# RN821X_RN721X_SOC_B register map
File version: v1.0.6
CPU: CM0 r0p0, little endian, no MPU, no FPU, 3 interrupt priority bits
Registers are 32-bit, read-write, reset 0x0 unless marked. A register's access mark holds for its fields unless they carry their own. Offsets are from the block's base; [hi:lo] are bit positions; {n}, {i} and the like mark numbered series; 'fields as' and 'values as' point back to an identical list.

## KBI — key detection
Base 0x40028000
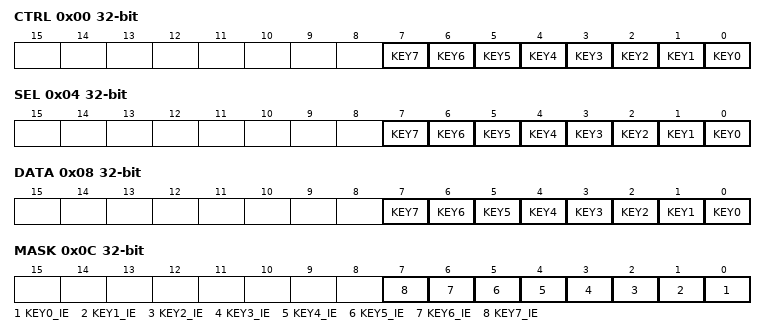
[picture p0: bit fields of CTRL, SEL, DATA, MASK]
0x00 CTRL — KBI control register
  [n] KEY{n} (n=0..7) — KBI KEY{n} enable/disable bit
    1=EN (KBI KEY{n} enable); 0=DIS (KBI KEY{n} disable)
0x04 SEL — KBI trigger mode select register
  [all] fields
    0=PE (KBI select posedge sampling); 1=NE (KBI select negedge sampling)
  [n] KEY{n} (n=0..7) — KBI KEY{n} posedge/negedge selection bit
0x08 DATA — KBI data register
  [all] fields
    1=PD (KEY pressed); 0=NUL (KEY not be pressed)
  [n] KEY{n} write-1-clears (n=0..7) — KBI KEY{n} data bit indicate key pressed or not
0x0C MASK — KBI interrupt mask register
  [n] KEY{n}_IE (n=0..7) — KBI KEY{n} interrupt enable/disable bit

## LCD — liquid crystal display
Base 0x40048000
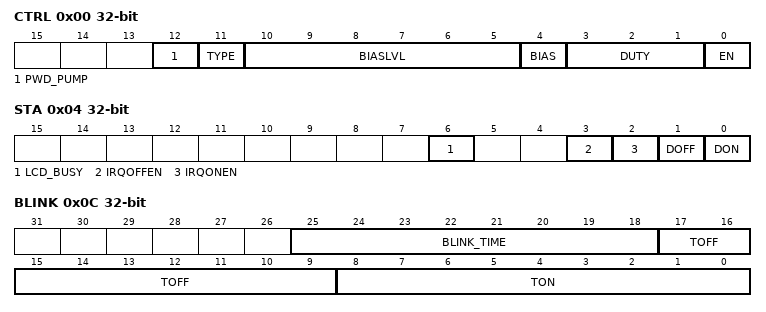
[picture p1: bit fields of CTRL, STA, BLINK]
0x00 CTRL — LCD control register
  [12] PWD_PUMP — LCD PUMP disable/enable bit
    0=EN (LCD PUMP enable); 1=DIS (LCD PUMP disable)
  [11] TYPE — LCD drive type selection bit
    0=A (select LCD drive type A as LCD drive type); 1=B (select LCD drive type B as LCD drive type)
  [10:5] BIASLVL — LCD voltage Bias configuration bits
  [4] BIAS — LCD voltage bias control bit
    0=1_3 (select LCD bias as 1/3 voltage bias); 1=1_4 (select LCD bias as 1/3 voltage bias)
  [3:1] DUTY — LCD duty cycle selection bits
    0=STA (static output (COM0)); 1=1_2 (duty cycle = 1/2 (COM0~1)); 2=1_3 (duty cycle = 1/3 (COM0~2)); 3=1_4 (duty cycle = 1/4 (COM0~3)); 4=1_6 (duty cycle = 1/6 (COM0~5)); 5=1_8 (duty cycle = 1/8 (COM0~7))
  [0] EN — LCD module enable/disable bit
0x04 STA — LCD status register
  [6] LCD_BUSY ro — LCD Busy Bit
  [3] IRQOFFEN — Display Off IRQ Enble Bit
  [2] IRQONEN — Display On IRQ Enble Bit
  [1] DOFF write-1-clears — Display Off Pending Bit
    0=NUL (LCD Display Off did not occured); 1=OCC (LCD Display Off occured)
  [0] DON write-1-clears — Display On Pending Bit
    0=NUL (LCD Display On did not occured); 1=OCC (LCD Display On occured)
0x08 CLKDIV — LCD clock divisor register
  [7:0] CLKDIV — LCD clock divisor configuration bits
0x0C BLINK — LCD blink control register
  [25:18] BLINK_TIME — blink duration configuration bits
  [17:9] TOFF — blink off duration configuration bits
  [8:0] TON — blink on duration configuration bits
0x10 PS — LCD PUMP set-up duration register
  [15:0] PS — PUMP Set-up duration configuration bits,duration equal to 30.5us * (4 + PS)
{0x20+i} BUF{i} 8-bit (i=0..35) — Data register of SEG({i}) COM[7:0]
  [7:0] BUF{i} — Data bits of SEG({i}) COM[7:0]
0x44 BUF36 8-bit — Data register of SEG(36) COM[7:1]
  [7:0] BUF36 — Data bits of SEG(36) COM[7:1]
0x45 BUF37 8-bit — Data register of SEG(37) COM[7:1]
  [7:0] BUF37 — Data bits of SEG(37) COM[7:1]

## NVM — no voltage module
Base 0x40040000
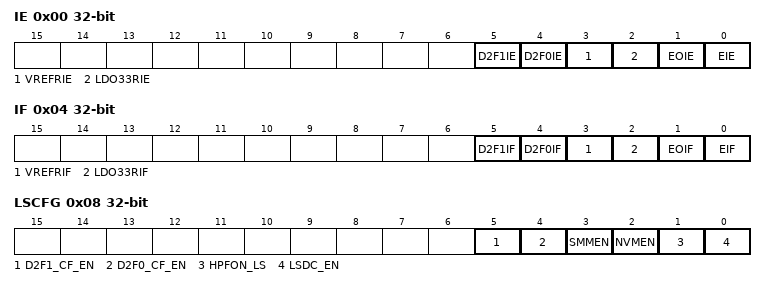
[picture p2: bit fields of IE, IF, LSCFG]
0x00 IE — interrupt enables
  [5] D2F1IE — d2f1 pulse interrupt enable
    0=DIS (do not generate interrupt when d2f1 pulse is output); 1=EN (generate interrupt when d2f1 pulse is output)
  [4] D2F0IE — d2f0 pulse interrupt enable
    0=DIS (do not generate interrupt when d2f0 pulse is output); 1=EN (generate interrupt when d2f0 pulse is output)
  [3] VREFRIE — VREF reset interrupt enable
    0=DIS (do not generate interrupt when VREF reset found); 1=EN (generate interrupt when VREF reset found)
  [2] LDO33RIE — LDO33 reset interrupt enable
    0=DIS (do not generate interrupt when reset found in LDO33 power domain); 1=EN (generate interrupt when reset found in LDO33 power domain)
  [1] EOIE — NV end and overflow interrupt enable
    0=DIS (do not generate interrupt when NV computation ends and NV value beyond threshold); 1=EN (generate interrupt when NV computation ends and NV value beyond threshold)
  [0] EIE — NV end interrupt enable
    0=DIS (do not generate interrupt when NV computation ends); 1=EN (generate interrupt when NV computation ends)
0x04 IF — interrupt flag
  [5] D2F1IF — d2f1 impulse interrupt flag
    0=NULL (no pending event of d2f1 impulse); 1=OCC (pending event of d2f1 impulse interrupt flag)
  [4] D2F0IF — d2f0 impulse interrupt flag
    0=NULL (no pending event of d2f0 impulse); 1=OCC (pending event of d2f0 impulse interrupt flag)
  [3] VREFRIF — VREF reset interrupt flag
    0=NULL (no pending event of VREF domain reset); 1=OCC (pending event of VREF domain reset found)
  [2] LDO33RIF — LDO33 reset interrupt flag
    0=NULL (no pending event of LDO33 power domain reset); 1=OCC (pending event of LDO33 power domain reset found)
  [1] EOIF — NV end and overflow interrupt flag
    0=NULL (no pending event of NV computation ends and NV value beyond threshold); 1=OCC (pending event of NV computation ends and NV value beyond threshold found)
  [0] EIF — NV end interrupt flag
    values as EOIF
0x08 LSCFG — NV config
  [5] D2F1_CF_EN — SMM enable
    0=DIS (D2F1 pulse not output to io); 1=EN (D2F1 pulse output to io)
  [4] D2F0_CF_EN — SMM enable
    0=DIS; 1=EN
  [3] SMMEN — SMM enable
    0=DIS (RMS updated every 20ms); 1=EN (RMS updated every 80ms)
  [2] NVMEN — module enable
    0=DIS (disabled); 1=EN (enabled)
  [1] HPFON_LS — high pass filter enable
    0=DIS (disabled); 1=EN (enabled)
  [0] LSDC_EN — automatic DC offset calibration enable
    0=DIS (disabled); 1=EN (enabled)
0x0C LSDCOS — NV measurement DC offset.
  [23:0] LSDCOS
0x10 LSTHO — NV measurement threshold
  [23:0] LSTHO
0x14 LSRMS ro — IA cyclic updated NV measurement RMS
  [23:0] LSRMS
0x18 LSRMS1 ro — IA RMS_L1 will not change after calculation
  [23:0] LSRMS1
0x20 HFCONST — HF const value
  [15:0] HFCONST
0x24 D2FP0 — D2F power 0 vaule
  [23:0] D2FP0
0x28 D2FP1 — D2F power 1 vaule
  [23:0] D2FP1
